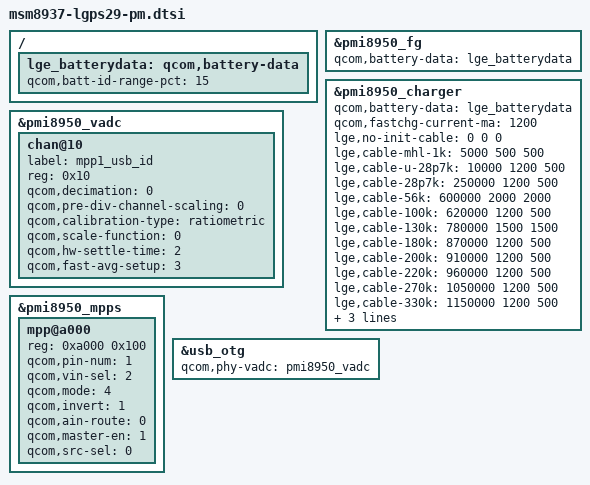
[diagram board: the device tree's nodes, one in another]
/*
 * Copyright (c) 2015, The Linux Foundation. All rights reserved.
 *
 * This program is free software; you can redistribute it and/or modify
 * it under the terms of the GNU General Public License version 2 and
 * only version 2 as published by the Free Software Foundation.
 *
 * This program is distributed in the hope that it will be useful,
 * but WITHOUT ANY WARRANTY; without even the implied warranty of
 * MERCHANTABILITY or FITNESS FOR A PARTICULAR PURPOSE.  See the
 * GNU General Public License for more details.
 */

/{
	lge_batterydata: qcom,battery-data {
		qcom,batt-id-range-pct = <15>;
		#include "../../qcom/batterydata-itech-3000mah.dtsi"
		#include "../../qcom/batterydata-ascent-3450mAh.dtsi"
	};
};

&pmi8950_fg {
	qcom,battery-data = <&lge_batterydata>;
};

&pmi8950_charger {
	qcom,battery-data = <&lge_batterydata>;
	qcom,fastchg-current-ma = <1200>;

	/* ref resistance 200K */
	lge,no-init-cable = <0 0 0>;
	lge,cable-mhl-1k = <5000 500 500>;
	lge,cable-u-28p7k = <10000 1200 500>;
	lge,cable-28p7k = <250000 1200 500>;
	lge,cable-56k = <600000 2000 2000>;
	lge,cable-100k = <620000 1200 500>;
	lge,cable-130k = <780000 1500 1500>;
	lge,cable-180k = <870000 1200 500>;
	lge,cable-200k = <910000 1200 500>;
	lge,cable-220k = <960000 1200 500>;
	lge,cable-270k = <1050000 1200 500>;
	lge,cable-330k = <1150000 1200 500>;
	lge,cable-620k = <1380000 1200 500>;
	lge,cable-910k = <1630000 2000 2000>;
	lge,cable-none = <1900000 1200  500>;
};

&pmi8950_vadc {
	chan@10 {
		label = "mpp1_usb_id";
		reg = <0x10>;
		qcom,decimation = <0>;
		qcom,pre-div-channel-scaling = <0>;
		qcom,calibration-type = "ratiometric";
		qcom,scale-function = <0>;
		qcom,hw-settle-time = <2>;
		qcom,fast-avg-setup = <3>;
	};
};

&pmi8950_mpps {
	mpp@a000 {
		reg = <0xa000 0x100>;
		qcom,pin-num = <1>;
		status = "okay";
		qcom,vin-sel = <2>;
		qcom,mode = <4>; /* AIN input */
		qcom,invert = <1>; /* Enable MPP */
		qcom,ain-route = <0>; /* AMUX 5 */
		qcom,master-en = <1>;
		qcom,src-sel = <0>; /* Function constant */
	};
};

&usb_otg {
	qcom,phy-vadc = <&pmi8950_vadc>;
};
